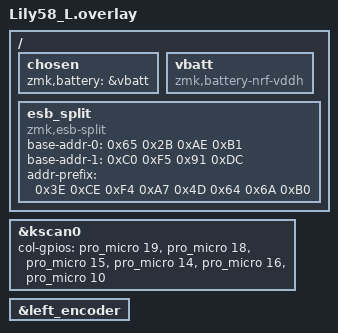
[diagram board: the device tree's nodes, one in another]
/*
 * Copyright (c) 2020 Pete Johanson
 *
 * SPDX-License-Identifier: MIT
 */

#include "Lily58.dtsi"

&kscan0 {
    col-gpios
        = <&pro_micro 19 GPIO_ACTIVE_HIGH>
        , <&pro_micro 18 GPIO_ACTIVE_HIGH>
        , <&pro_micro 15 GPIO_ACTIVE_HIGH>
        , <&pro_micro 14 GPIO_ACTIVE_HIGH>
        , <&pro_micro 16 GPIO_ACTIVE_HIGH>
        , <&pro_micro 10 GPIO_ACTIVE_HIGH>
        ;
};

&left_encoder {
    status = "okay";
};
/ {
    chosen {
      zmk,battery = &vbatt;
    };

    vbatt: vbatt {
        compatible = "zmk,battery-nrf-vddh";
    };

    // Must be byte-identical to Lily58_R.overlay and Lily58_dongle.overlay.
    esb_split {
        compatible = "zmk,esb-split";
        base-addr-0 = <0x65 0x2B 0xAE 0xB1>;
        base-addr-1 = <0xC0 0xF5 0x91 0xDC>;
        addr-prefix = <0x3E 0xCE 0xF4 0xA7 0x4D 0x64 0x6A 0xB0>;
    };
};
